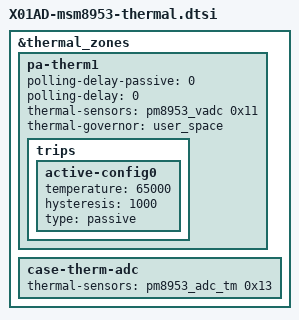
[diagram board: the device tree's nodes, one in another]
/* Copyright (c) 2018, The Linux Foundation. All rights reserved.
 *
 * This program is free software; you can redistribute it and/or modify
 * it under the terms of the GNU General Public License version 2 and
 * only version 2 as published by the Free Software Foundation.
 *
 * This program is distributed in the hope that it will be useful,
 * but WITHOUT ANY WARRANTY; without even the implied warranty of
 * MERCHANTABILITY or FITNESS FOR A PARTICULAR PURPOSE.  See the
 * GNU General Public License for more details.
 */

&thermal_zones {
	pa-therm1 {
		polling-delay-passive = <0>;
		polling-delay = <0>;
		thermal-sensors = <&pm8953_vadc 0x11>;
		thermal-governor = "user_space";

		trips {
			active-config0 {
				temperature = <65000>;
				hysteresis = <1000>;
				type = "passive";
			};
		};
	};

	case-therm-adc {
		thermal-sensors = <&pm8953_adc_tm 0x13>;
	};
};
